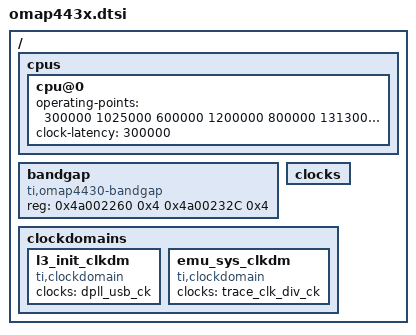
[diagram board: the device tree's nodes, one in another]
/*
 * Device Tree Source for OMAP443x SoC
 *
 * Copyright (C) 2013 Texas Instruments Incorporated - http://www.ti.com/
 *
 * This file is licensed under the terms of the GNU General Public License
 * version 2.  This program is licensed "as is" without any warranty of any
 * kind, whether express or implied.
 */

#include "omap4.dtsi"

/ {
	cpus {
		cpu@0 {
			/* OMAP443x variants OPP50-OPPNT */
			operating-points = <
				/* kHz    uV */
				300000  1025000
				600000  1200000
				800000  1313000
				1008000 1375000
			>;
			clock-latency = <300000>; /* From legacy driver */
		};
	};

	bandgap {
		reg = <0x4a002260 0x4
		       0x4a00232C 0x4>;
		compatible = "ti,omap4430-bandgap";
	};

	clocks {
		#address-cells = <1>;
		#size-cells = <1>;
		ranges;
		/include/ "omap44xx-clocks.dtsi"
		/include/ "omap443x-clocks.dtsi"
	};

	clockdomains {
		l3_init_clkdm: l3_init_clkdm {
			compatible = "ti,clockdomain";
			clocks = <&dpll_usb_ck>;
		};

		emu_sys_clkdm: emu_sys_clkdm {
			compatible = "ti,clockdomain";
			clocks = <&trace_clk_div_ck>;
		};
	};
};
